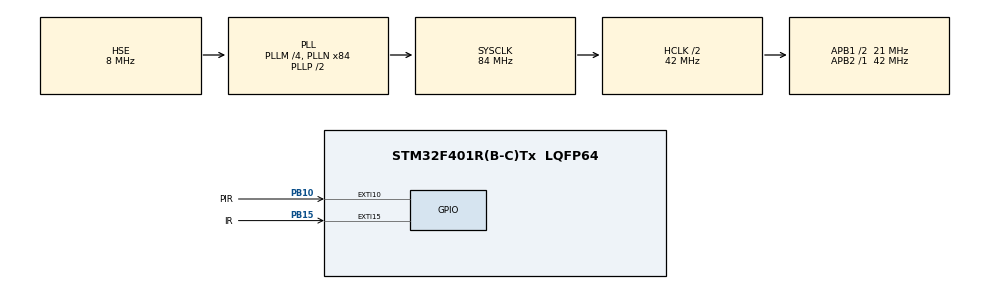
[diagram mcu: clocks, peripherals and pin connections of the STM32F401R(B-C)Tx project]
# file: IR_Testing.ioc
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FREERTOS.BinarySemaphores01=PIR_Sem01,Dynamic,NULL;IR_Sem02,Dynamic,NULL
FREERTOS.Tasks01=PIR_Task01,0,128,Task1_PIR,Default,NULL,Dynamic,NULL,NULL;IR_Task02,0,128,Task2_IR,Default,NULL,Dynamic,NULL,NULL
FREERTOS.configTICK_RATE_HZ=100
Mcu.Family=STM32F4
Mcu.Name=STM32F401R(B-C)Tx
Mcu.Package=LQFP64
NVIC.EXTI15_10_IRQn=true\:0\:0\:false\:false\:true\:false\:true\:true
NVIC.PriorityGroup=NVIC_PRIORITYGROUP_4
NVIC.TIM1_UP_TIM10_IRQn=true\:15\:0\:false\:false\:true\:false\:false\:true
NVIC.TimeBase=TIM1_UP_TIM10_IRQn
NVIC.TimeBaseIP=TIM10
PA13.Mode=Serial_Wire
PA13.Signal=SYS_JTMS-SWDIO
PA14.Mode=Serial_Wire
PA14.Signal=SYS_JTCK-SWCLK
PB10.GPIO_Label=PIR
PB10.Signal=GPXTI10
PB15.GPIO_Label=IR
PB15.Signal=GPXTI15
PC14-OSC32_IN.Mode=LSE-External-Oscillator
PC14-OSC32_IN.Signal=RCC_OSC32_IN
PC15-OSC32_OUT.Mode=LSE-External-Oscillator
PC15-OSC32_OUT.Signal=RCC_OSC32_OUT
PH0\ -\ OSC_IN.Mode=HSE-External-Oscillator
PH0\ -\ OSC_IN.Signal=RCC_OSC_IN
PH1\ -\ OSC_OUT.Mode=HSE-External-Oscillator
PH1\ -\ OSC_OUT.Signal=RCC_OSC_OUT
ProjectManager.HeapSize=0x200
ProjectManager.StackSize=0x400
ProjectManager.TargetToolchain=STM32CubeIDE
RCC.48MHZClocksFreq_Value=42000000
RCC.AHBCLKDivider=RCC_SYSCLK_DIV2
RCC.AHBFreq_Value=42000000
RCC.APB1CLKDivider=RCC_HCLK_DIV2
RCC.APB1Freq_Value=21000000
RCC.APB1TimFreq_Value=42000000
RCC.APB2Freq_Value=42000000
RCC.APB2TimFreq_Value=42000000
RCC.CortexFreq_Value=42000000
RCC.HCLKFreq_Value=42000000
RCC.HSE_VALUE=8000000
RCC.HSI_VALUE=16000000
RCC.PLLM=4
RCC.PLLN=84
RCC.PLLSourceVirtual=RCC_PLLSOURCE_HSE
RCC.SYSCLKFreq_VALUE=84000000
RCC.SYSCLKSource=RCC_SYSCLKSOURCE_PLLCLK
RCC.VCOOutputFreq_Value=168000000
VP_FREERTOS_VS_CMSIS_V1.Mode=CMSIS_V1
VP_SYS_VS_tim10.Mode=TIM10
board=custom

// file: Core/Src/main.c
/* USER CODE BEGIN Header */
/**
  ******************************************************************************
  * @file           : main.c
  * @brief          : Main program body
  ******************************************************************************
  * @attention
  *
  * Copyright (c) 2023 STMicroelectronics.
  * All rights reserved.
  *
  * This software is licensed under terms that can be found in the LICENSE file
  * in the root directory of this software component.
  * If no LICENSE file comes with this software, it is provided AS-IS.
  *
  ******************************************************************************
  */
/* USER CODE END Header */
#include "main.h"
#include "cmsis_os.h"

/* USER CODE BEGIN Includes */
#include<stdio.h>
/* USER CODE END Includes */

osThreadId PIR_Task01Handle;
osThreadId IR_Task02Handle;
osSemaphoreId PIR_Sem01Handle;
osSemaphoreId IR_Sem02Handle;
/* USER CODE BEGIN PV */

uint8_t IR_Data,PIR_Data;

/* USER CODE END PV */

void SystemClock_Config(void);
static void MX_GPIO_Init(void);
void Task1_PIR(void const * argument);
void Task2_IR(void const * argument);

/* USER CODE BEGIN 0 */
//void HAL_GPIO_EXTI_Callback( uint16_t GPIO_Pin)
//{
//	if(GPIO_Pin == USER_Btn_Pin){
//	   PIR_Data = HAL_GPIO_ReadPin(GPIOB, PIR_Pin);
//	}
//}
/* USER CODE END 0 */

int main(void)
{

  /* MCU Configuration--------------------------------------------------------*/

  /* Reset of all peripherals, Initializes the Flash interface and the Systick. */
  HAL_Init();

  /* Configure the system clock */
  SystemClock_Config();

  /* Initialize all configured peripherals */
  MX_GPIO_Init();

  /* Create the semaphores(s) */
  /* definition and creation of PIR_Sem01 */
  osSemaphoreDef(PIR_Sem01);
  PIR_Sem01Handle = osSemaphoreCreate(osSemaphore(PIR_Sem01), 1);

  /* definition and creation of IR_Sem02 */
  osSemaphoreDef(IR_Sem02);
  IR_Sem02Handle = osSemaphoreCreate(osSemaphore(IR_Sem02), 1);

  /* Create the thread(s) */
  /* definition and creation of PIR_Task01 */
  osThreadDef(PIR_Task01, Task1_PIR, osPriorityNormal, 0, 128);
  PIR_Task01Handle = osThreadCreate(osThread(PIR_Task01), NULL);

  /* definition and creation of IR_Task02 */
  osThreadDef(IR_Task02, Task2_IR, osPriorityNormal, 0, 128);
  IR_Task02Handle = osThreadCreate(osThread(IR_Task02), NULL);

  /* Start scheduler */
  osKernelStart();

  /* We should never get here as control is now taken by the scheduler */
  /* Infinite loop */
  while (1)
  {

  }
}

void SystemClock_Config(void)
{
  RCC_OscInitTypeDef RCC_OscInitStruct = {0};
  RCC_ClkInitTypeDef RCC_ClkInitStruct = {0};

  /** Configure the main internal regulator output voltage
  */
  __HAL_RCC_PWR_CLK_ENABLE();
  __HAL_PWR_VOLTAGESCALING_CONFIG(PWR_REGULATOR_VOLTAGE_SCALE2);
  /** Initializes the RCC Oscillators according to the specified parameters
  * in the RCC_OscInitTypeDef structure.
  */
  RCC_OscInitStruct.OscillatorType = RCC_OSCILLATORTYPE_HSE;
  RCC_OscInitStruct.HSEState = RCC_HSE_ON;
  RCC_OscInitStruct.PLL.PLLState = RCC_PLL_ON;
  RCC_OscInitStruct.PLL.PLLSource = RCC_PLLSOURCE_HSE;
  RCC_OscInitStruct.PLL.PLLM = 4;
  RCC_OscInitStruct.PLL.PLLN = 84;
  RCC_OscInitStruct.PLL.PLLP = RCC_PLLP_DIV2;
  RCC_OscInitStruct.PLL.PLLQ = 4;
  if (HAL_RCC_OscConfig(&RCC_OscInitStruct) != HAL_OK)
  {
    Error_Handler();
  }
  /** Initializes the CPU, AHB and APB buses clocks
  */
  RCC_ClkInitStruct.ClockType = RCC_CLOCKTYPE_HCLK|RCC_CLOCKTYPE_SYSCLK
                              |RCC_CLOCKTYPE_PCLK1|RCC_CLOCKTYPE_PCLK2;
  RCC_ClkInitStruct.SYSCLKSource = RCC_SYSCLKSOURCE_PLLCLK;
  RCC_ClkInitStruct.AHBCLKDivider = RCC_SYSCLK_DIV2;
  RCC_ClkInitStruct.APB1CLKDivider = RCC_HCLK_DIV2;
  RCC_ClkInitStruct.APB2CLKDivider = RCC_HCLK_DIV1;

  if (HAL_RCC_ClockConfig(&RCC_ClkInitStruct, FLASH_LATENCY_1) != HAL_OK)
  {
    Error_Handler();
  }
}

static void MX_GPIO_Init(void)
{
  GPIO_InitTypeDef GPIO_InitStruct = {0};

  /* GPIO Ports Clock Enable */
  __HAL_RCC_GPIOC_CLK_ENABLE();
  __HAL_RCC_GPIOH_CLK_ENABLE();
  __HAL_RCC_GPIOB_CLK_ENABLE();
  __HAL_RCC_GPIOA_CLK_ENABLE();

  /*Configure GPIO pins : PIR_Pin IR_Pin */
  GPIO_InitStruct.Pin = PIR_Pin|IR_Pin;
  GPIO_InitStruct.Mode = GPIO_MODE_IT_RISING;
  GPIO_InitStruct.Pull = GPIO_NOPULL;
  HAL_GPIO_Init(GPIOB, &GPIO_InitStruct);

  /* EXTI interrupt init*/
  HAL_NVIC_SetPriority(EXTI15_10_IRQn, 0, 0);
  HAL_NVIC_EnableIRQ(EXTI15_10_IRQn);

}

void Task1_PIR(void const * argument)
{
  /* USER CODE BEGIN 5 */
  /* Infinite loop */
  for(;;)
  {
	HAL_GPIO_EXTI_Callback(PIR_Pin);
	PIR_Data =  HAL_GPIO_ReadPin(GPIOB,PIR_Pin);
    osDelay(10);
  }
  /* USER CODE END 5 */
}

void Task2_IR(void const * argument)
{
  /* USER CODE BEGIN Task2_IR */
  /* Infinite loop */
  for(;;)
  {
	  HAL_GPIO_EXTI_Callback(IR_Pin);
	  IR_Data =  HAL_GPIO_ReadPin(GPIOB,IR_Pin);
	  osDelay(10);
  }
  /* USER CODE END Task2_IR */
}

void HAL_TIM_PeriodElapsedCallback(TIM_HandleTypeDef *htim)
{
  if (htim->Instance == TIM10) {
    HAL_IncTick();
  }
}

void Error_Handler(void)
{
  __disable_irq();
  while (1)
  {
  }
}
